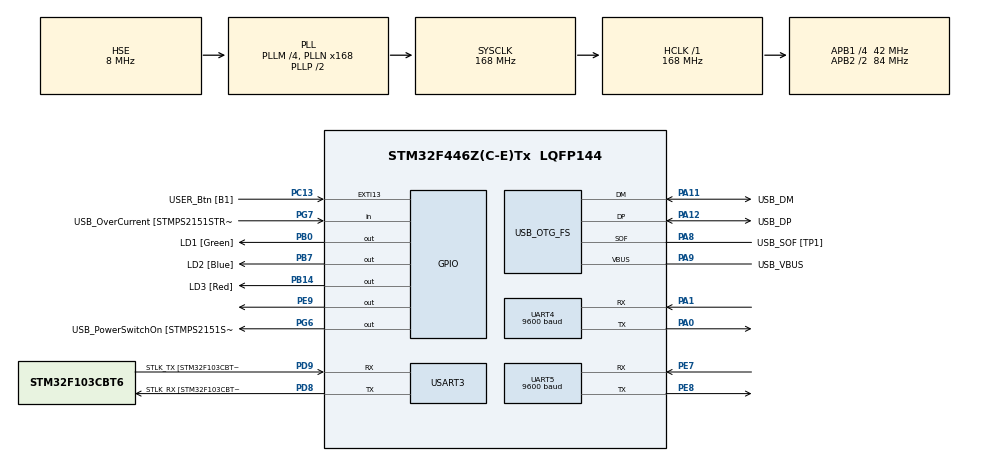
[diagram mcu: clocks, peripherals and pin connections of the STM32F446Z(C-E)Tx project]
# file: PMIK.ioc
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Dma.Request0=UART4_RX
Dma.Request1=UART5_RX
Dma.Request2=UART4_TX
Dma.Request3=UART5_TX
Dma.UART4_RX.0.Direction=DMA_PERIPH_TO_MEMORY
Dma.UART4_RX.0.FIFOMode=DMA_FIFOMODE_DISABLE
Dma.UART4_RX.0.Instance=DMA1_Stream2
Dma.UART4_RX.0.MemDataAlignment=DMA_MDATAALIGN_BYTE
Dma.UART4_RX.0.MemInc=DMA_MINC_ENABLE
Dma.UART4_RX.0.Mode=DMA_CIRCULAR
Dma.UART4_RX.0.PeriphDataAlignment=DMA_PDATAALIGN_BYTE
Dma.UART4_RX.0.PeriphInc=DMA_PINC_DISABLE
Dma.UART4_RX.0.Priority=DMA_PRIORITY_MEDIUM
Dma.UART4_TX.2.Direction=DMA_MEMORY_TO_PERIPH
Dma.UART4_TX.2.FIFOMode=DMA_FIFOMODE_DISABLE
Dma.UART4_TX.2.Instance=DMA1_Stream4
Dma.UART4_TX.2.MemDataAlignment=DMA_MDATAALIGN_BYTE
Dma.UART4_TX.2.MemInc=DMA_MINC_ENABLE
Dma.UART4_TX.2.Mode=DMA_NORMAL
Dma.UART4_TX.2.PeriphDataAlignment=DMA_PDATAALIGN_BYTE
Dma.UART4_TX.2.PeriphInc=DMA_PINC_DISABLE
Dma.UART4_TX.2.Priority=DMA_PRIORITY_MEDIUM
Dma.UART5_RX.1.Direction=DMA_PERIPH_TO_MEMORY
Dma.UART5_RX.1.FIFOMode=DMA_FIFOMODE_DISABLE
Dma.UART5_RX.1.Instance=DMA1_Stream0
Dma.UART5_RX.1.MemDataAlignment=DMA_MDATAALIGN_BYTE
Dma.UART5_RX.1.MemInc=DMA_MINC_ENABLE
Dma.UART5_RX.1.Mode=DMA_CIRCULAR
Dma.UART5_RX.1.PeriphDataAlignment=DMA_PDATAALIGN_BYTE
Dma.UART5_RX.1.PeriphInc=DMA_PINC_DISABLE
Dma.UART5_RX.1.Priority=DMA_PRIORITY_MEDIUM
Dma.UART5_TX.3.Direction=DMA_MEMORY_TO_PERIPH
Dma.UART5_TX.3.FIFOMode=DMA_FIFOMODE_DISABLE
Dma.UART5_TX.3.Instance=DMA1_Stream7
Dma.UART5_TX.3.MemDataAlignment=DMA_MDATAALIGN_BYTE
Dma.UART5_TX.3.MemInc=DMA_MINC_ENABLE
Dma.UART5_TX.3.Mode=DMA_NORMAL
Dma.UART5_TX.3.PeriphDataAlignment=DMA_PDATAALIGN_BYTE
Dma.UART5_TX.3.PeriphInc=DMA_PINC_DISABLE
Dma.UART5_TX.3.Priority=DMA_PRIORITY_MEDIUM
Mcu.Family=STM32F4
Mcu.Name=STM32F446Z(C-E)Tx
Mcu.Package=LQFP144
NVIC.DMA1_Stream0_IRQn=true\:0\:0\:false\:false\:true\:false\:true
NVIC.DMA1_Stream2_IRQn=true\:0\:0\:false\:false\:true\:false\:true
NVIC.DMA1_Stream4_IRQn=true\:0\:0\:false\:false\:true\:false\:true
NVIC.DMA1_Stream7_IRQn=true\:0\:0\:false\:false\:true\:false\:true
NVIC.PriorityGroup=NVIC_PRIORITYGROUP_4
NVIC.TIM3_IRQn=true\:0\:0\:false\:false\:true\:true\:true
NVIC.UART4_IRQn=true\:0\:0\:false\:false\:true\:true\:true
NVIC.UART5_IRQn=true\:0\:0\:false\:false\:true\:true\:true
PA0-WKUP.Mode=Asynchronous
PA0-WKUP.Signal=UART4_TX
PA1.Mode=Asynchronous
PA1.Signal=UART4_RX
PA10.GPIO_Label=USB_ID
PA10.Signal=USB_OTG_FS_ID
PA11.GPIO_Label=USB_DM
PA11.Mode=Device_Only
PA11.Signal=USB_OTG_FS_DM
PA12.GPIO_Label=USB_DP
PA12.Mode=Device_Only
PA12.Signal=USB_OTG_FS_DP
PA13.GPIO_Label=TMS
PA13.Mode=Serial_Wire
PA13.Signal=SYS_JTMS-SWDIO
PA14.GPIO_Label=TCK
PA14.Mode=Serial_Wire
PA14.Signal=SYS_JTCK-SWCLK
PA8.GPIO_Label=USB_SOF [TP1]
PA8.Mode=Activate_SOF_FS
PA8.Signal=USB_OTG_FS_SOF
PA9.GPIO_Label=USB_VBUS
PA9.Mode=Activate_VBUS
PA9.Signal=USB_OTG_FS_VBUS
PB0.GPIO_Label=LD1 [Green]
PB0.Signal=GPIO_Output
PB14.GPIO_Label=LD3 [Red]
PB14.Signal=GPIO_Output
PB7.GPIO_Label=LD2 [Blue]
PB7.Signal=GPIO_Output
PC13.GPIO_Label=USER_Btn [B1]
PC13.Signal=GPXTI13
PC14-OSC32_IN.Mode=LSE-External-Oscillator
PC14-OSC32_IN.Signal=RCC_OSC32_IN
PC15-OSC32_OUT.Mode=LSE-External-Oscillator
PC15-OSC32_OUT.Signal=RCC_OSC32_OUT
PD8.GPIO_Label=STLK_RX [STM32F103CBT6_PA3]
PD8.Mode=Asynchronous
PD8.Signal=USART3_TX
PD9.GPIO_Label=STLK_TX [STM32F103CBT6_PA2]
PD9.Mode=Asynchronous
PD9.Signal=USART3_RX
PE7.Mode=Asynchronous
PE7.Signal=UART5_RX
PE8.Mode=Asynchronous
PE8.Signal=UART5_TX
PE9.Signal=GPIO_Output
PG6.GPIO_Label=USB_PowerSwitchOn [STMPS2151STR_EN]
PG6.Signal=GPIO_Output
PG7.GPIO_Label=USB_OverCurrent [STMPS2151STR_FAULT]
PG7.Signal=GPIO_Input
PH0-OSC_IN.GPIO_Label=MCO [STM32F103CBT6_PA8]
PH0-OSC_IN.Mode=HSE-External-Clock-Source
PH0-OSC_IN.Signal=RCC_OSC_IN
PH1-OSC_OUT.Mode=HSE-External-Clock-Source
PH1-OSC_OUT.Signal=RCC_OSC_OUT
ProjectManager.HeapSize=0x200
ProjectManager.StackSize=0x400
ProjectManager.TargetToolchain=STM32CubeIDE
RCC.48MHZClocksFreq_Value=24000000
RCC.AHBFreq_Value=168000000
RCC.APB1CLKDivider=RCC_HCLK_DIV4
RCC.APB1Freq_Value=42000000
RCC.APB1TimFreq_Value=84000000
RCC.APB2CLKDivider=RCC_HCLK_DIV2
RCC.APB2Freq_Value=84000000
RCC.APB2TimFreq_Value=168000000
RCC.CortexFreq_Value=168000000
RCC.HCLKFreq_Value=168000000
RCC.HSE_VALUE=8000000
RCC.HSI_VALUE=16000000
RCC.PLLM=4
RCC.PLLMUL=RCC_PLL_MUL9
RCC.PLLN=168
RCC.PLLQ=7
RCC.PRESCALERUSB=RCC_USBCLKSOURCE_PLL_DIV1_5
RCC.SYSCLKFreq_VALUE=168000000
RCC.SYSCLKSource=RCC_SYSCLKSOURCE_PLLCLK
RCC.SYSCLKSourceVirtual=RCC_SYSCLKSOURCE_PLLCLK
RCC.USBFreq_Value=48000000
RCC.VCOOutputFreq_Value=336000000
TIM3.Period=20507
TIM3.Prescaler=16384
UART4.BaudRate=9600
UART4.VirtualMode=Asynchronous
UART5.BaudRate=9600
UART5.VirtualMode=Asynchronous
USART3.VirtualMode=VM_ASYNC
USB_OTG_FS.VirtualMode=Device_Only
VP_TIM3_VS_ClockSourceINT.Mode=Internal
board=NUCLEO-F446ZE

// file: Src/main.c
/* USER CODE BEGIN Header */
/**
  ******************************************************************************
  * @file           : main.c
  * @brief          : Main program body
  ******************************************************************************
  * @attention
  *
  * <h2><center>&copy; Copyright (c) 2020 STMicroelectronics.
  * All rights reserved.</center></h2>
  *
  * This software component is licensed by ST under BSD 3-Clause license,
  * the "License"; You may not use this file except in compliance with the
  * License. You may obtain a copy of the License at:
  *                        opensource.org/licenses/BSD-3-Clause
  *
  ******************************************************************************
  */
/* USER CODE END Header */

#include "main.h"

/* USER CODE BEGIN Includes */
#include "uart_dma.h"
#include "gps.h"
#include "bluetooth.h"
/* USER CODE END Includes */

TIM_HandleTypeDef htim3;

UART_HandleTypeDef huart4;
UART_HandleTypeDef huart5;
UART_HandleTypeDef huart3;
DMA_HandleTypeDef hdma_uart4_rx;
DMA_HandleTypeDef hdma_uart4_tx;
DMA_HandleTypeDef hdma_uart5_rx;
DMA_HandleTypeDef hdma_uart5_tx;

PCD_HandleTypeDef hpcd_USB_OTG_FS;

/* USER CODE BEGIN PV */
UART_DMA_HandleTypeDef 		huart_dma_1;
UART_DMA_HandleTypeDef 		huart_dma_2;
GPS_TypeDef 				hgps;
Blue_Frame_HandleTypeDef 	hblue;
/* USER CODE END PV */

void SystemClock_Config(void);
static void MX_GPIO_Init(void);
static void MX_DMA_Init(void);
static void MX_TIM3_Init(void);
static void MX_UART4_Init(void);
static void MX_UART5_Init(void);
static void MX_USART3_UART_Init(void);
static void MX_USB_OTG_FS_PCD_Init(void);

int main(void)
{

  /* MCU Configuration--------------------------------------------------------*/

  /* Reset of all peripherals, Initializes the Flash interface and the Systick. */
  HAL_Init();

  /* Configure the system clock */
  SystemClock_Config();

  /* Initialize all configured peripherals */
  MX_GPIO_Init();
  MX_DMA_Init();
  MX_TIM3_Init();
  MX_UART4_Init();
  MX_UART5_Init();
  MX_USART3_UART_Init();
  MX_USB_OTG_FS_PCD_Init();
  /* USER CODE BEGIN 2 */
  uart_dma_init(&huart_dma_1, &huart4, &hdma_uart4_tx, &hdma_uart4_rx);
  uart_dma_init(&huart_dma_2, &huart5, &hdma_uart5_tx, &hdma_uart5_rx);

  gps_init(&hgps, &huart_dma_1);
  blue_parser_init(&hblue, &huart_dma_2);

  HAL_TIM_Base_Start_IT(&htim3);
  /* USER CODE END 2 */

  /* Infinite loop */
  while (1)
  {

  }
}

void SystemClock_Config(void)
{
  RCC_OscInitTypeDef RCC_OscInitStruct = {0};
  RCC_ClkInitTypeDef RCC_ClkInitStruct = {0};
  RCC_PeriphCLKInitTypeDef PeriphClkInitStruct = {0};

  /** Configure the main internal regulator output voltage
  */
  __HAL_RCC_PWR_CLK_ENABLE();
  __HAL_PWR_VOLTAGESCALING_CONFIG(PWR_REGULATOR_VOLTAGE_SCALE1);
  /** Initializes the CPU, AHB and APB busses clocks
  */
  RCC_OscInitStruct.OscillatorType = RCC_OSCILLATORTYPE_HSE;
  RCC_OscInitStruct.HSEState = RCC_HSE_BYPASS;
  RCC_OscInitStruct.PLL.PLLState = RCC_PLL_ON;
  RCC_OscInitStruct.PLL.PLLSource = RCC_PLLSOURCE_HSE;
  RCC_OscInitStruct.PLL.PLLM = 4;
  RCC_OscInitStruct.PLL.PLLN = 168;
  RCC_OscInitStruct.PLL.PLLP = RCC_PLLP_DIV2;
  RCC_OscInitStruct.PLL.PLLQ = 7;
  RCC_OscInitStruct.PLL.PLLR = 2;
  if (HAL_RCC_OscConfig(&RCC_OscInitStruct) != HAL_OK)
  {
    Error_Handler();
  }
  /** Initializes the CPU, AHB and APB busses clocks
  */
  RCC_ClkInitStruct.ClockType = RCC_CLOCKTYPE_HCLK|RCC_CLOCKTYPE_SYSCLK
                              |RCC_CLOCKTYPE_PCLK1|RCC_CLOCKTYPE_PCLK2;
  RCC_ClkInitStruct.SYSCLKSource = RCC_SYSCLKSOURCE_PLLCLK;
  RCC_ClkInitStruct.AHBCLKDivider = RCC_SYSCLK_DIV1;
  RCC_ClkInitStruct.APB1CLKDivider = RCC_HCLK_DIV4;
  RCC_ClkInitStruct.APB2CLKDivider = RCC_HCLK_DIV2;

  if (HAL_RCC_ClockConfig(&RCC_ClkInitStruct, FLASH_LATENCY_5) != HAL_OK)
  {
    Error_Handler();
  }
  PeriphClkInitStruct.PeriphClockSelection = RCC_PERIPHCLK_CLK48;
  PeriphClkInitStruct.Clk48ClockSelection = RCC_CLK48CLKSOURCE_PLLQ;
  if (HAL_RCCEx_PeriphCLKConfig(&PeriphClkInitStruct) != HAL_OK)
  {
    Error_Handler();
  }
}

static void MX_TIM3_Init(void)
{

  TIM_ClockConfigTypeDef sClockSourceConfig = {0};
  TIM_MasterConfigTypeDef sMasterConfig = {0};

  htim3.Instance = TIM3;
  htim3.Init.Prescaler = 16384;
  htim3.Init.CounterMode = TIM_COUNTERMODE_UP;
  htim3.Init.Period = 20507;
  htim3.Init.ClockDivision = TIM_CLOCKDIVISION_DIV1;
  htim3.Init.AutoReloadPreload = TIM_AUTORELOAD_PRELOAD_DISABLE;
  if (HAL_TIM_Base_Init(&htim3) != HAL_OK)
  {
    Error_Handler();
  }
  sClockSourceConfig.ClockSource = TIM_CLOCKSOURCE_INTERNAL;
  if (HAL_TIM_ConfigClockSource(&htim3, &sClockSourceConfig) != HAL_OK)
  {
    Error_Handler();
  }
  sMasterConfig.MasterOutputTrigger = TIM_TRGO_RESET;
  sMasterConfig.MasterSlaveMode = TIM_MASTERSLAVEMODE_DISABLE;
  if (HAL_TIMEx_MasterConfigSynchronization(&htim3, &sMasterConfig) != HAL_OK)
  {
    Error_Handler();
  }

}

static void MX_UART4_Init(void)
{

  huart4.Instance = UART4;
  huart4.Init.BaudRate = 9600;
  huart4.Init.WordLength = UART_WORDLENGTH_8B;
  huart4.Init.StopBits = UART_STOPBITS_1;
  huart4.Init.Parity = UART_PARITY_NONE;
  huart4.Init.Mode = UART_MODE_TX_RX;
  huart4.Init.HwFlowCtl = UART_HWCONTROL_NONE;
  huart4.Init.OverSampling = UART_OVERSAMPLING_16;
  if (HAL_UART_Init(&huart4) != HAL_OK)
  {
    Error_Handler();
  }

}

static void MX_UART5_Init(void)
{

  huart5.Instance = UART5;
  huart5.Init.BaudRate = 9600;
  huart5.Init.WordLength = UART_WORDLENGTH_8B;
  huart5.Init.StopBits = UART_STOPBITS_1;
  huart5.Init.Parity = UART_PARITY_NONE;
  huart5.Init.Mode = UART_MODE_TX_RX;
  huart5.Init.HwFlowCtl = UART_HWCONTROL_NONE;
  huart5.Init.OverSampling = UART_OVERSAMPLING_16;
  if (HAL_UART_Init(&huart5) != HAL_OK)
  {
    Error_Handler();
  }

}

static void MX_USART3_UART_Init(void)
{

  huart3.Instance = USART3;
  huart3.Init.BaudRate = 115200;
  huart3.Init.WordLength = UART_WORDLENGTH_8B;
  huart3.Init.StopBits = UART_STOPBITS_1;
  huart3.Init.Parity = UART_PARITY_NONE;
  huart3.Init.Mode = UART_MODE_TX_RX;
  huart3.Init.HwFlowCtl = UART_HWCONTROL_NONE;
  huart3.Init.OverSampling = UART_OVERSAMPLING_16;
  if (HAL_UART_Init(&huart3) != HAL_OK)
  {
    Error_Handler();
  }

}

static void MX_USB_OTG_FS_PCD_Init(void)
{

  hpcd_USB_OTG_FS.Instance = USB_OTG_FS;
  hpcd_USB_OTG_FS.Init.dev_endpoints = 6;
  hpcd_USB_OTG_FS.Init.speed = PCD_SPEED_FULL;
  hpcd_USB_OTG_FS.Init.dma_enable = DISABLE;
  hpcd_USB_OTG_FS.Init.phy_itface = PCD_PHY_EMBEDDED;
  hpcd_USB_OTG_FS.Init.Sof_enable = ENABLE;
  hpcd_USB_OTG_FS.Init.low_power_enable = DISABLE;
  hpcd_USB_OTG_FS.Init.lpm_enable = DISABLE;
  hpcd_USB_OTG_FS.Init.vbus_sensing_enable = ENABLE;
  hpcd_USB_OTG_FS.Init.use_dedicated_ep1 = DISABLE;
  if (HAL_PCD_Init(&hpcd_USB_OTG_FS) != HAL_OK)
  {
    Error_Handler();
  }

}

static void MX_DMA_Init(void)
{

  /* DMA controller clock enable */
  __HAL_RCC_DMA1_CLK_ENABLE();

  /* DMA interrupt init */
  /* DMA1_Stream0_IRQn interrupt configuration */
  HAL_NVIC_SetPriority(DMA1_Stream0_IRQn, 0, 0);
  HAL_NVIC_EnableIRQ(DMA1_Stream0_IRQn);
  /* DMA1_Stream2_IRQn interrupt configuration */
  HAL_NVIC_SetPriority(DMA1_Stream2_IRQn, 0, 0);
  HAL_NVIC_EnableIRQ(DMA1_Stream2_IRQn);
  /* DMA1_Stream4_IRQn interrupt configuration */
  HAL_NVIC_SetPriority(DMA1_Stream4_IRQn, 0, 0);
  HAL_NVIC_EnableIRQ(DMA1_Stream4_IRQn);
  /* DMA1_Stream7_IRQn interrupt configuration */
  HAL_NVIC_SetPriority(DMA1_Stream7_IRQn, 0, 0);
  HAL_NVIC_EnableIRQ(DMA1_Stream7_IRQn);

}

static void MX_GPIO_Init(void)
{
  GPIO_InitTypeDef GPIO_InitStruct = {0};

  /* GPIO Ports Clock Enable */
  __HAL_RCC_GPIOC_CLK_ENABLE();
  __HAL_RCC_GPIOH_CLK_ENABLE();
  __HAL_RCC_GPIOA_CLK_ENABLE();
  __HAL_RCC_GPIOB_CLK_ENABLE();
  __HAL_RCC_GPIOE_CLK_ENABLE();
  __HAL_RCC_GPIOD_CLK_ENABLE();
  __HAL_RCC_GPIOG_CLK_ENABLE();

  /*Configure GPIO pin Output Level */
  HAL_GPIO_WritePin(GPIOB, LD1_Pin|LD3_Pin|LD2_Pin, GPIO_PIN_RESET);

  /*Configure GPIO pin Output Level */
  HAL_GPIO_WritePin(GPIOE, GPIO_PIN_9, GPIO_PIN_RESET);

  /*Configure GPIO pin Output Level */
  HAL_GPIO_WritePin(USB_PowerSwitchOn_GPIO_Port, USB_PowerSwitchOn_Pin, GPIO_PIN_RESET);

  /*Configure GPIO pin : USER_Btn_Pin */
  GPIO_InitStruct.Pin = USER_Btn_Pin;
  GPIO_InitStruct.Mode = GPIO_MODE_IT_RISING;
  GPIO_InitStruct.Pull = GPIO_NOPULL;
  HAL_GPIO_Init(USER_Btn_GPIO_Port, &GPIO_InitStruct);

  /*Configure GPIO pins : LD1_Pin LD3_Pin LD2_Pin */
  GPIO_InitStruct.Pin = LD1_Pin|LD3_Pin|LD2_Pin;
  GPIO_InitStruct.Mode = GPIO_MODE_OUTPUT_PP;
  GPIO_InitStruct.Pull = GPIO_NOPULL;
  GPIO_InitStruct.Speed = GPIO_SPEED_FREQ_LOW;
  HAL_GPIO_Init(GPIOB, &GPIO_InitStruct);

  /*Configure GPIO pin : PE9 */
  GPIO_InitStruct.Pin = GPIO_PIN_9;
  GPIO_InitStruct.Mode = GPIO_MODE_OUTPUT_PP;
  GPIO_InitStruct.Pull = GPIO_NOPULL;
  GPIO_InitStruct.Speed = GPIO_SPEED_FREQ_LOW;
  HAL_GPIO_Init(GPIOE, &GPIO_InitStruct);

  /*Configure GPIO pin : USB_PowerSwitchOn_Pin */
  GPIO_InitStruct.Pin = USB_PowerSwitchOn_Pin;
  GPIO_InitStruct.Mode = GPIO_MODE_OUTPUT_PP;
  GPIO_InitStruct.Pull = GPIO_NOPULL;
  GPIO_InitStruct.Speed = GPIO_SPEED_FREQ_LOW;
  HAL_GPIO_Init(USB_PowerSwitchOn_GPIO_Port, &GPIO_InitStruct);

  /*Configure GPIO pin : USB_OverCurrent_Pin */
  GPIO_InitStruct.Pin = USB_OverCurrent_Pin;
  GPIO_InitStruct.Mode = GPIO_MODE_INPUT;
  GPIO_InitStruct.Pull = GPIO_NOPULL;
  HAL_GPIO_Init(USB_OverCurrent_GPIO_Port, &GPIO_InitStruct);

}

void Error_Handler(void)
{
}

/************************ (C) COPYRIGHT STMicroelectronics *****END OF FILE****/
